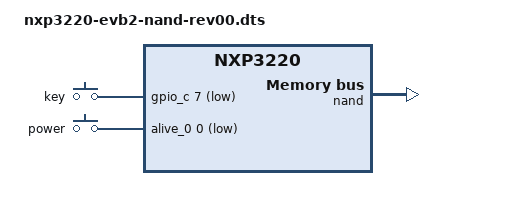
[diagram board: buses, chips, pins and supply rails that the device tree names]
// SPDX-License-Identifier: (GPL-2.0+ OR MIT)
/*
 * Copyright (C) 2018  Nexell Co., Ltd.
 * Author: JungHyun, Kim <jhkim@nexell.co.kr>
 */

/dts-v1/;

#include "nxp3220-evb2-common.dtsi"

/ {
	compatible = "nexell,nxp3220-evb2-nand", "nexell,nxp3220";
};

&dwmmc_0 {
	status = "disabled";
};

&nand {
	status = "okay";

	nand-ecc-strength = <4>;
	nand-ecc-step-size = <512>;
	nand-timing-mode = <4>;

	partitions {
		compatible = "fixed-partitions";
		#address-cells = <1>;
		#size-cells = <1>;

		bootsector@0 {
			label = "bootsector";
			reg = <0x0000000 0x500000>;
		     /*	read-only; */
		};

		env@500000 {
			label = "env";
			reg = <0x0500000 0x100000>;
		     /*	read-only; */
		};

		boot@600000 {
			label = "boot";
			reg = <0x0600000 0x2000000>;
		};

		misc@2600000 {
			label = "misc";
			reg = <0x2600000 0x0800000>;
		};

		rootfs@2e00000 {
			label = "rootfs";
			reg = <0x2e00000 0x5200000>;
		};
	};
};

&gpio_keys {
	pinctrl-names = "default";
	pinctrl-0 = <&button_key>, <&button_pwr>;

	button@key {
		label = "key";
		gpios = <&gpio_c 7 GPIO_ACTIVE_LOW>;
		linux,code = <KEY_BACK>;
	};

	button@pwr {
		label = "power";
		gpios = <&alive_0 0 GPIO_ACTIVE_LOW>;
		linux,code = <KEY_POWER>;
		gpio-key,wakeup;
	};
};
